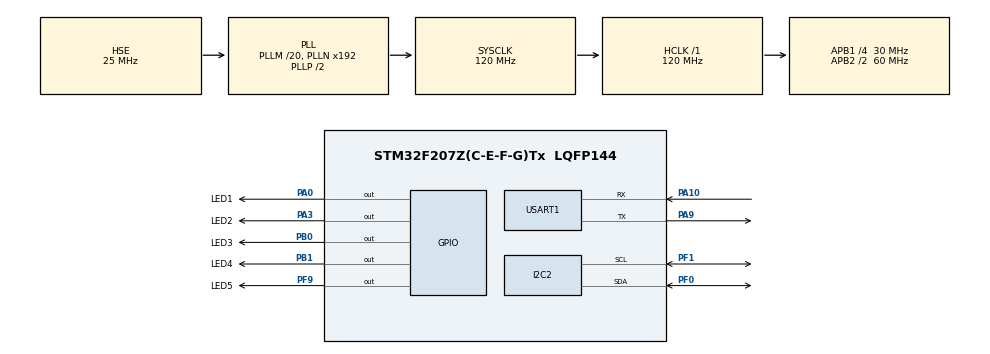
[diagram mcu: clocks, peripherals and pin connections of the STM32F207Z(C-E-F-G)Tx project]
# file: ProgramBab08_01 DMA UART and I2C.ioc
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Dma.I2C2_RX.2.Direction=DMA_PERIPH_TO_MEMORY
Dma.I2C2_RX.2.FIFOMode=DMA_FIFOMODE_DISABLE
Dma.I2C2_RX.2.Instance=DMA1_Stream2
Dma.I2C2_RX.2.MemDataAlignment=DMA_MDATAALIGN_BYTE
Dma.I2C2_RX.2.MemInc=DMA_MINC_ENABLE
Dma.I2C2_RX.2.Mode=DMA_NORMAL
Dma.I2C2_RX.2.PeriphDataAlignment=DMA_PDATAALIGN_BYTE
Dma.I2C2_RX.2.PeriphInc=DMA_PINC_DISABLE
Dma.I2C2_RX.2.Priority=DMA_PRIORITY_HIGH
Dma.I2C2_TX.3.Direction=DMA_MEMORY_TO_PERIPH
Dma.I2C2_TX.3.FIFOMode=DMA_FIFOMODE_DISABLE
Dma.I2C2_TX.3.Instance=DMA1_Stream7
Dma.I2C2_TX.3.MemDataAlignment=DMA_MDATAALIGN_BYTE
Dma.I2C2_TX.3.MemInc=DMA_MINC_ENABLE
Dma.I2C2_TX.3.Mode=DMA_NORMAL
Dma.I2C2_TX.3.PeriphDataAlignment=DMA_PDATAALIGN_BYTE
Dma.I2C2_TX.3.PeriphInc=DMA_PINC_DISABLE
Dma.I2C2_TX.3.Priority=DMA_PRIORITY_HIGH
Dma.Request0=USART1_RX
Dma.Request1=USART1_TX
Dma.Request2=I2C2_RX
Dma.Request3=I2C2_TX
Dma.USART1_RX.0.Direction=DMA_PERIPH_TO_MEMORY
Dma.USART1_RX.0.FIFOMode=DMA_FIFOMODE_DISABLE
Dma.USART1_RX.0.Instance=DMA2_Stream2
Dma.USART1_RX.0.MemDataAlignment=DMA_MDATAALIGN_BYTE
Dma.USART1_RX.0.MemInc=DMA_MINC_ENABLE
Dma.USART1_RX.0.Mode=DMA_NORMAL
Dma.USART1_RX.0.PeriphDataAlignment=DMA_PDATAALIGN_BYTE
Dma.USART1_RX.0.PeriphInc=DMA_PINC_DISABLE
Dma.USART1_RX.0.Priority=DMA_PRIORITY_HIGH
Dma.USART1_TX.1.Direction=DMA_MEMORY_TO_PERIPH
Dma.USART1_TX.1.FIFOMode=DMA_FIFOMODE_DISABLE
Dma.USART1_TX.1.Instance=DMA2_Stream7
Dma.USART1_TX.1.MemDataAlignment=DMA_MDATAALIGN_BYTE
Dma.USART1_TX.1.MemInc=DMA_MINC_ENABLE
Dma.USART1_TX.1.Mode=DMA_NORMAL
Dma.USART1_TX.1.PeriphDataAlignment=DMA_PDATAALIGN_BYTE
Dma.USART1_TX.1.PeriphInc=DMA_PINC_DISABLE
Dma.USART1_TX.1.Priority=DMA_PRIORITY_HIGH
Mcu.Family=STM32F2
Mcu.Name=STM32F207Z(C-E-F-G)Tx
Mcu.Package=LQFP144
NVIC.DMA1_Stream2_IRQn=true\:0\:0\:false\:false\:true\:false\:true
NVIC.DMA1_Stream7_IRQn=true\:0\:0\:false\:false\:true\:false\:true
NVIC.DMA2_Stream2_IRQn=true\:0\:0\:false\:false\:true\:false\:true
NVIC.DMA2_Stream7_IRQn=true\:0\:0\:false\:false\:true\:false\:true
NVIC.I2C2_ER_IRQn=true\:0\:0\:false\:false\:true\:true\:true
NVIC.I2C2_EV_IRQn=true\:0\:0\:false\:false\:true\:true\:true
NVIC.PriorityGroup=NVIC_PRIORITYGROUP_4
NVIC.USART1_IRQn=true\:0\:0\:false\:false\:true\:true\:true
PA0-WKUP.GPIO_Label=LED1
PA0-WKUP.Signal=GPIO_Output
PA10.Mode=Asynchronous
PA10.Signal=USART1_RX
PA3.GPIO_Label=LED2
PA3.Signal=GPIO_Output
PA9.Mode=Asynchronous
PA9.Signal=USART1_TX
PB0.GPIO_Label=LED3
PB0.Signal=GPIO_Output
PB1.GPIO_Label=LED4
PB1.Signal=GPIO_Output
PF0.Mode=I2C
PF0.Signal=I2C2_SDA
PF1.Mode=I2C
PF1.Signal=I2C2_SCL
PF9.GPIO_Label=LED5
PF9.Signal=GPIO_Output
PH0-OSC_IN.Mode=HSE-External-Oscillator
PH0-OSC_IN.Signal=RCC_OSC_IN
PH1-OSC_OUT.Mode=HSE-External-Oscillator
PH1-OSC_OUT.Signal=RCC_OSC_OUT
ProjectManager.HeapSize=0x200
ProjectManager.StackSize=0x400
ProjectManager.TargetToolchain=STM32CubeIDE
RCC.48MHZClocksFreq_Value=60000000
RCC.AHBFreq_Value=120000000
RCC.APB1CLKDivider=RCC_HCLK_DIV4
RCC.APB1Freq_Value=30000000
RCC.APB1TimFreq_Value=60000000
RCC.APB2CLKDivider=RCC_HCLK_DIV2
RCC.APB2Freq_Value=60000000
RCC.APB2TimFreq_Value=120000000
RCC.CortexFreq_Value=120000000
RCC.HCLKFreq_Value=120000000
RCC.HSE_VALUE=25000000
RCC.HSI_VALUE=16000000
RCC.LSE_VALUE=32768
RCC.PLLM=20
RCC.PLLSourceVirtual=RCC_PLLSOURCE_HSE
RCC.SYSCLKFreq_VALUE=120000000
RCC.SYSCLKSource=RCC_SYSCLKSOURCE_PLLCLK
RCC.VCOOutputFreq_Value=240000000
USART1.VirtualMode=VM_ASYNC
board=custom

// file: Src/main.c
/* USER CODE BEGIN Header */
/**
  ******************************************************************************
  * @file           : main.c
  * @brief          : Main program body
  ******************************************************************************
  * @attention
  *
  * <h2><center>&copy; Copyright (c) 2019 STMicroelectronics.
  * All rights reserved.</center></h2>
  *
  * This software component is licensed by ST under BSD 3-Clause license,
  * the "License"; You may not use this file except in compliance with the
  * License. You may obtain a copy of the License at:
  *                        opensource.org/licenses/BSD-3-Clause
  *
  ******************************************************************************
  */
/* USER CODE END Header */

#include "main.h"
#include "dma.h"
#include "i2c.h"
#include "usart.h"
#include "gpio.h"

/* USER CODE BEGIN Includes */
#include "global.h"
/* USER CODE END Includes */

void SystemClock_Config(void);

int main(void)
{

  /* MCU Configuration--------------------------------------------------------*/

  /* Reset of all peripherals, Initializes the Flash interface and the Systick. */
  HAL_Init();

  /* Configure the system clock */
  SystemClock_Config();

  /* Initialize all configured peripherals */
  MX_GPIO_Init();
  MX_DMA_Init();
  MX_USART1_UART_Init();
  MX_I2C2_Init();
  /* USER CODE BEGIN 2 */
  printf("DMA Test UART & I2C\r\n");
  LED_Default();

  //Start DMA Receive for UART
  if(HAL_UART_Receive_DMA(&huart1, (uint8_t*)&UartRxBuffer, 1)!=HAL_OK){
	Error_Handler();
  }

  /* USER CODE END 2 */

  /* Infinite loop */
  while (1)
  {

    /* USER CODE BEGIN 3 */
	  LED_Operation();
	  if(pcframe){
		  pc_link();
	  }

  }
  /* USER CODE END 3 */
}

void SystemClock_Config(void)
{
  RCC_OscInitTypeDef RCC_OscInitStruct = {0};
  RCC_ClkInitTypeDef RCC_ClkInitStruct = {0};

  /** Initializes the CPU, AHB and APB busses clocks
  */
  RCC_OscInitStruct.OscillatorType = RCC_OSCILLATORTYPE_HSE;
  RCC_OscInitStruct.HSEState = RCC_HSE_ON;
  RCC_OscInitStruct.PLL.PLLState = RCC_PLL_ON;
  RCC_OscInitStruct.PLL.PLLSource = RCC_PLLSOURCE_HSE;
  RCC_OscInitStruct.PLL.PLLM = 20;
  RCC_OscInitStruct.PLL.PLLN = 192;
  RCC_OscInitStruct.PLL.PLLP = RCC_PLLP_DIV2;
  RCC_OscInitStruct.PLL.PLLQ = 4;
  if (HAL_RCC_OscConfig(&RCC_OscInitStruct) != HAL_OK)
  {
    Error_Handler();
  }
  /** Initializes the CPU, AHB and APB busses clocks
  */
  RCC_ClkInitStruct.ClockType = RCC_CLOCKTYPE_HCLK|RCC_CLOCKTYPE_SYSCLK
                              |RCC_CLOCKTYPE_PCLK1|RCC_CLOCKTYPE_PCLK2;
  RCC_ClkInitStruct.SYSCLKSource = RCC_SYSCLKSOURCE_PLLCLK;
  RCC_ClkInitStruct.AHBCLKDivider = RCC_SYSCLK_DIV1;
  RCC_ClkInitStruct.APB1CLKDivider = RCC_HCLK_DIV4;
  RCC_ClkInitStruct.APB2CLKDivider = RCC_HCLK_DIV2;

  if (HAL_RCC_ClockConfig(&RCC_ClkInitStruct, FLASH_LATENCY_3) != HAL_OK)
  {
    Error_Handler();
  }
}

void Error_Handler(void)
{
}

/************************ (C) COPYRIGHT STMicroelectronics *****END OF FILE****/
